# CY8C5888LTI_LP097 register map
File version: 0.1
Registers are 8-bit, read-write, no defined reset value unless marked. A register's access mark holds for its fields unless they carry their own. Offsets are from the block's base; [hi:lo] are bit positions; 'fields as' and 'values as' point back to an identical list.

## PWM_1
Base 0x00000000
0x400043A3 PWM_1_GLOBAL_ENABLE — PM.ACT.CFG
  [3:0] en_timer — Enable timer/counters.
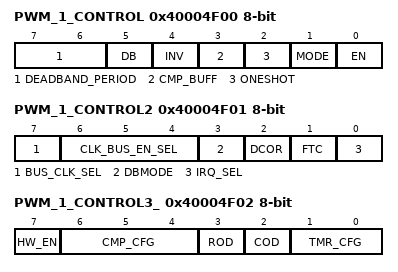
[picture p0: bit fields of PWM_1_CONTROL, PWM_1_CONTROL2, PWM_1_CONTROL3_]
0x40004F00 PWM_1_CONTROL — TMRx.CFG0
  [7:6] DEADBAND_PERIOD
  [5] DB — Deadband mode--Deadband phases phi1 and phi2 are outputted on CMP and TC output pins respectively.
    0=Timer (CMP and TC are output.); 1=Deadband (PHI1 (instead of CMP) and PHI2 (instead of TC) are output.)
  [4] INV — Invert sense of TIMEREN signal
  [3] CMP_BUFF — Buffer compare register. Compare register updates only on timer terminal count.
  [2] ONESHOT — Timer stops upon reaching stop condition defined by TMR_CFG bits. Can be restarted by asserting TIMER RESET or disabling and re-enabling block.
  [1] MODE ro — Mode. (0 = Timer; 1 = Comparator)
    0=Timer mode. CNT/CMP register holds timer count value.; 1=Comparator mode. CNT/CMP register holds comparator threshold value.
  [0] EN — Enables timer/comparator.
0x40004F01 PWM_1_CONTROL2 — TMRx.CFG1
  [7] BUS_CLK_SEL — Bus Clock selection.
  [6:4] CLK_BUS_EN_SEL — Digital Global Clock selection.
  [3] DBMODE — Deadband mode (asynchronous/synchronous). CMP output pin is also affected when not in deadband mode (CFG0.DEADBAND).
  [2] DCOR — Disable Clear on Read (DCOR) of Status Register SR0.
  [1] FTC — First Terminal Count (FTC). Setting this bit forces a single pulse on the TC pin when first enabled.
    0=Disable_FTC (Disable the single cycle pulse, which signifies the timer is starting.); 1=Enable_FTC (Enable the single cycle pulse, which signifies the timer is starting.)
  [0] IRQ_SEL — Irq selection. (0 = raw interrupts; 1 = status register interrupts)
0x40004F02 PWM_1_CONTROL3_ — TMRx.CFG2
  [7] HW_EN — When set Timer Enable controls counting.
  [6:4] CMP_CFG — Comparator configurations
    0=Equal (Compare Equal); 1=Less_than (Compare Less Than); 2=Less_than_or_equal (Compare Less Than or Equal .); 3=Greater (Compare Greater Than .); 4=Greater_than_or_equal (Compare Greater Than or Equal)
  [3] ROD — Reset On Disable (ROD). Resets internal state of output logic
  [2] COD — Clear On Disable (COD). Clears or gates outputs to zero.
  [1:0] TMR_CFG — Timer configuration (MODE = 0): 000 = Continuous; 001 = Pulsewidth; 010 = Period; 011 = Stop on IRQ
    0=Continuous (Timer runs while EN bit of CFG0 register is set to '1'.); 1=Pulsewidth (Timer runs from positive to negative edge of TIMEREN.); 2=Period (Timer runs from positive to positive edge of TIMEREN.); 3=Irq (Timer runs until IRQ.)
0x40004F04 PWM_1_PERIOD 16-bit — TMRx.PER0 - Assigned Period
0x40004F06 PWM_1_COMPARE 16-bit — TMRx.CNT_CMP0 - Assigned Compare Value

## GPIO_Control_Reg
Base 0x00000000
0x40006576 GPIO_Control_Reg_CONTROL_REG

## RpiInterrupts
Base 0x00000000
0x4000657A RpiInterrupts_CONTROL_REG

## Status_Reg_1
Base 0x00000000
0x40006567 Status_Reg_1_STATUS_REG
0x40006587 Status_Reg_1_MASK_REG
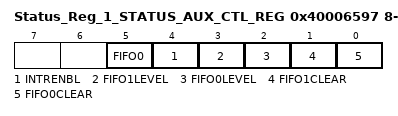
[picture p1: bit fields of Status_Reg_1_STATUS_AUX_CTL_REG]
0x40006597 Status_Reg_1_STATUS_AUX_CTL_REG
  [5] FIFO0 — FIFO0 clear
    1=ENABLED (Enable counter); 0=DISABLED (Disable counter)
  [4] INTRENBL — Enables or disables the Interrupt
    1=ENABLED (Interrupt enabled); 0=DISABLED (Interrupt disabled)
  [3] FIFO1LEVEL — FIFO level
    1=ENABLED (FIFO LVL: input mode: FIFO at least 1/2 empty; output mode: FIFO at least 1/2 full); 0=DISABLED (FIFO LVL: input mode: FIFO not full; output mode: FIFO not empty)
  [2] FIFO0LEVEL — FIFO level
    values as FIFO1LEVEL
  [1] FIFO1CLEAR — FIFO clear
    1=ENABLED (Clear FIFO state); 0=DISABLED (Normal FIFO operation)
  [0] FIFO0CLEAR — FIFO clear
    values as FIFO1CLEAR

## EnableBattery
Base 0x00000000
0x40006479 EnableBattery_CONTROL_REG

## SPIS
Base 0x00000000
0x4000640C SPIS_TX_DATA 16-bit
0x4000640C SPIS_RX_DATA 16-bit
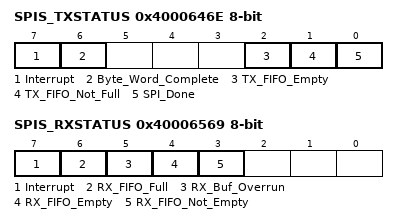
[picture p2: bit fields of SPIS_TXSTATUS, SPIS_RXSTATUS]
0x4000646E SPIS_TXSTATUS
  [7] Interrupt ro — Set when interrupt occurs
  [6] Byte_Word_Complete ro — Set when a byte/word transmit has completed
  [2] TX_FIFO_Empty ro — Set when the TX Data FIFO is empty
  [1] TX_FIFO_Not_Full ro — Set when the TX Data FIFO is not full
  [0] SPI_Done ro — Set when all of the data in the transmit FIFO has been sent. Set when Byte/Word Complete has been set and TX Data FIFO is empty
0x40006569 SPIS_RXSTATUS
  [7] Interrupt ro — Set when interrupt occurs
  [6] RX_FIFO_Full ro — Set when the RX Data FIFO is full
  [5] RX_Buf_Overrun ro — Set when RX Data has overrun the 4 byte/word FIFO without being moved to the RX buffer cmemory array (if one exists)
  [4] RX_FIFO_Empty ro — Set when the RX Data FIFO is empty
  [3] RX_FIFO_Not_Empty ro — Set when the RX Data FIFO is not empty. That is, at least one byte/word is in the RX FIFO

## Control_Reg_SS_1
Base 0x00000000
0x40006474 Control_Reg_SS_1_CONTROL_REG
